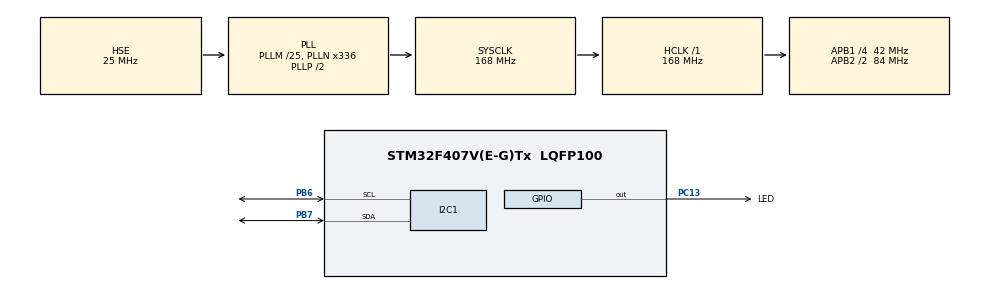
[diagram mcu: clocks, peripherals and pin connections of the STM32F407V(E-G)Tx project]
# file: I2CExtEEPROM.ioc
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Mcu.Family=STM32F4
Mcu.Name=STM32F407V(E-G)Tx
Mcu.Package=LQFP100
NVIC.PriorityGroup=NVIC_PRIORITYGROUP_4
PA13.Mode=Serial_Wire
PA13.Signal=SYS_JTMS-SWDIO
PA14.Mode=Serial_Wire
PA14.Signal=SYS_JTCK-SWCLK
PB6.Mode=I2C
PB6.Signal=I2C1_SCL
PB7.Mode=I2C
PB7.Signal=I2C1_SDA
PC13-ANTI_TAMP.GPIO_Label=LED
PC13-ANTI_TAMP.PinState=GPIO_PIN_SET
PC13-ANTI_TAMP.Signal=GPIO_Output
PH0-OSC_IN.Mode=HSE-External-Oscillator
PH0-OSC_IN.Signal=RCC_OSC_IN
PH1-OSC_OUT.Mode=HSE-External-Oscillator
PH1-OSC_OUT.Signal=RCC_OSC_OUT
ProjectManager.HeapSize=0x200
ProjectManager.StackSize=0x400
ProjectManager.TargetToolchain=MDK-ARM V5.32
RCC.48MHZClocksFreq_Value=84000000
RCC.AHBFreq_Value=168000000
RCC.APB1CLKDivider=RCC_HCLK_DIV4
RCC.APB1Freq_Value=42000000
RCC.APB1TimFreq_Value=84000000
RCC.APB2CLKDivider=RCC_HCLK_DIV2
RCC.APB2Freq_Value=84000000
RCC.APB2TimFreq_Value=168000000
RCC.CortexFreq_Value=168000000
RCC.HCLKFreq_Value=168000000
RCC.HSE_VALUE=25000000
RCC.HSI_VALUE=16000000
RCC.LSE_VALUE=32768
RCC.PLLM=25
RCC.PLLN=336
RCC.PLLSourceVirtual=RCC_PLLSOURCE_HSE
RCC.SYSCLKFreq_VALUE=168000000
RCC.SYSCLKSource=RCC_SYSCLKSOURCE_PLLCLK
RCC.VCOOutputFreq_Value=336000000
board=custom

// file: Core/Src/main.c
/* USER CODE BEGIN Header */
/**
  ******************************************************************************
  * @file           : main.c
  * @brief          : Main program body
  ******************************************************************************
  * @attention
  *
  * Copyright (c) 2024 STMicroelectronics.
  * All rights reserved.
  *
  * This software is licensed under terms that can be found in the LICENSE file
  * in the root directory of this software component.
  * If no LICENSE file comes with this software, it is provided AS-IS.
  *
  ******************************************************************************
  */
/* USER CODE END Header */
#include "main.h"
#include "i2c.h"
#include "gpio.h"

/* USER CODE BEGIN PD */

#define DeviceAddress 0x50

/* USER CODE END PD */

/* USER CODE BEGIN PV */

uint16_t myAddress = 1;
uint8_t myData_tx = 120;
uint8_t myData_rx = 0;

uint8_t FLAG_ERROR = 0;

/* USER CODE END PV */

void SystemClock_Config(void);
/* USER CODE BEGIN PFP */

HAL_StatusTypeDef byte_write(uint8_t dev_add, uint16_t add, uint8_t data)
{
	HAL_StatusTypeDef status;
	uint8_t ee[3];

	dev_add <<= 1;
	ee[0] = (add >> 8); //H
	ee[1] = add;				//L
	ee[2] = data;
	status = HAL_I2C_Master_Transmit(&hi2c1, dev_add, ee, 3, 100);
	HAL_Delay(5);
	return status;
}

HAL_StatusTypeDef random_read(uint8_t dev_add, uint16_t add, uint8_t *data)
{
	HAL_StatusTypeDef status, status1, status2;
	uint8_t ee[2];

	dev_add <<= 1;
	ee[0] = (add >> 8); //H
	ee[1] = add;				//L
	status1 = HAL_I2C_Master_Transmit(&hi2c1, dev_add, ee, 2, 100);
	HAL_Delay(5);
	status2 = HAL_I2C_Master_Receive(&hi2c1, dev_add, data, 1, 100);
	HAL_Delay(5);

	if(status1 == HAL_OK && status2 == HAL_OK)
		status = HAL_OK;
	else
		status = HAL_ERROR;
	return status;
}

/* USER CODE END PFP */

int main(void)
{

  /* MCU Configuration--------------------------------------------------------*/

  /* Reset of all peripherals, Initializes the Flash interface and the Systick. */
  HAL_Init();

  /* Configure the system clock */
  SystemClock_Config();

  /* Initialize all configured peripherals */
  MX_GPIO_Init();
  MX_I2C1_Init();
  /* USER CODE BEGIN 2 */

//	if(HAL_I2C_IsDeviceReady(&hi2c1, (DeviceAddress << 1), 3, 100) == HAL_OK)
//	{
//		if(byte_write(DeviceAddress, myAddress, myData_tx) == HAL_OK)
//		{
//			if(random_read(DeviceAddress, myAddress, &myData_rx) == HAL_OK)
//			{
//				//OK
//				HAL_GPIO_WritePin(LED_GPIO_Port, LED_Pin, GPIO_PIN_RESET);
//			}
//			else
//			{
//				FLAG_ERROR = 1;
//			}
//		}
//		else
//		{
//			FLAG_ERROR = 1;
//		}
//	}
//	else
//	{
//		FLAG_ERROR = 1;
//	}

	if(HAL_I2C_IsDeviceReady(&hi2c1, (DeviceAddress << 1), 3, 100) == HAL_OK)
	{
		if(HAL_I2C_Mem_Write(&hi2c1, (DeviceAddress << 1), myAddress, I2C_MEMADD_SIZE_16BIT, &myData_tx, 1, 100) == HAL_OK)
		{
			HAL_Delay(5);
			if(HAL_I2C_Mem_Read(&hi2c1, (DeviceAddress << 1), myAddress, I2C_MEMADD_SIZE_16BIT, &myData_rx, 1, 100) == HAL_OK)
			{
				//OK
				HAL_GPIO_WritePin(LED_GPIO_Port, LED_Pin, GPIO_PIN_RESET);
			}
			else
			{
				FLAG_ERROR = 1;
			}
		}
		else
		{
			FLAG_ERROR = 1;
		}
	}
	else
	{
		FLAG_ERROR = 1;
	}

  /* USER CODE END 2 */

  /* Infinite loop */
  /* USER CODE BEGIN WHILE */
  while (1)
  {
		if(FLAG_ERROR == 1)
			HAL_GPIO_TogglePin(LED_GPIO_Port, LED_Pin);

    /* USER CODE END WHILE */

  }
}

void SystemClock_Config(void)
{
  RCC_OscInitTypeDef RCC_OscInitStruct = {0};
  RCC_ClkInitTypeDef RCC_ClkInitStruct = {0};

  /** Configure the main internal regulator output voltage
  */
  __HAL_RCC_PWR_CLK_ENABLE();
  __HAL_PWR_VOLTAGESCALING_CONFIG(PWR_REGULATOR_VOLTAGE_SCALE1);

  /** Initializes the RCC Oscillators according to the specified parameters
  * in the RCC_OscInitTypeDef structure.
  */
  RCC_OscInitStruct.OscillatorType = RCC_OSCILLATORTYPE_HSE;
  RCC_OscInitStruct.HSEState = RCC_HSE_ON;
  RCC_OscInitStruct.PLL.PLLState = RCC_PLL_ON;
  RCC_OscInitStruct.PLL.PLLSource = RCC_PLLSOURCE_HSE;
  RCC_OscInitStruct.PLL.PLLM = 25;
  RCC_OscInitStruct.PLL.PLLN = 336;
  RCC_OscInitStruct.PLL.PLLP = RCC_PLLP_DIV2;
  RCC_OscInitStruct.PLL.PLLQ = 4;
  if (HAL_RCC_OscConfig(&RCC_OscInitStruct) != HAL_OK)
  {
    Error_Handler();
  }

  /** Initializes the CPU, AHB and APB buses clocks
  */
  RCC_ClkInitStruct.ClockType = RCC_CLOCKTYPE_HCLK|RCC_CLOCKTYPE_SYSCLK
                              |RCC_CLOCKTYPE_PCLK1|RCC_CLOCKTYPE_PCLK2;
  RCC_ClkInitStruct.SYSCLKSource = RCC_SYSCLKSOURCE_PLLCLK;
  RCC_ClkInitStruct.AHBCLKDivider = RCC_SYSCLK_DIV1;
  RCC_ClkInitStruct.APB1CLKDivider = RCC_HCLK_DIV4;
  RCC_ClkInitStruct.APB2CLKDivider = RCC_HCLK_DIV2;

  if (HAL_RCC_ClockConfig(&RCC_ClkInitStruct, FLASH_LATENCY_5) != HAL_OK)
  {
    Error_Handler();
  }
}

void Error_Handler(void)
{
  __disable_irq();
  while (1)
  {
  }
}
